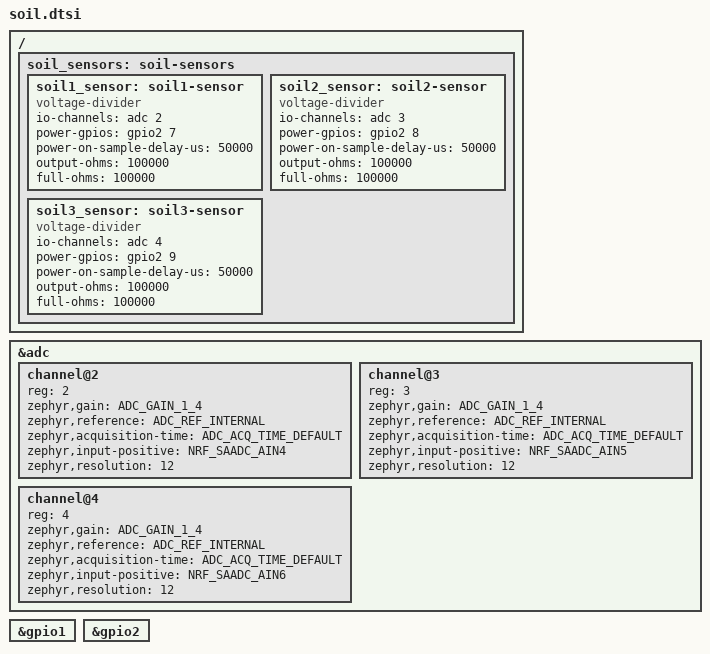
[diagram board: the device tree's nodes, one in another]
&adc {
	status = "okay";
	#address-cells = <1>;
	#size-cells = <0>;

	channel@2 {
		reg = <2>;
		zephyr,gain = "ADC_GAIN_1_4";
		zephyr,reference = "ADC_REF_INTERNAL";
		zephyr,acquisition-time = <ADC_ACQ_TIME_DEFAULT>;
		zephyr,input-positive = <NRF_SAADC_AIN4>; /* P1.11 */
		zephyr,resolution = <12>;
	};

	channel@3 {
		reg = <3>;
		zephyr,gain = "ADC_GAIN_1_4";
		zephyr,reference = "ADC_REF_INTERNAL";
		zephyr,acquisition-time = <ADC_ACQ_TIME_DEFAULT>;
		zephyr,input-positive = <NRF_SAADC_AIN5>; /* P1.12 */
		zephyr,resolution = <12>;
	};

	channel@4 {
		reg = <4>;
		zephyr,gain = "ADC_GAIN_1_4";
		zephyr,reference = "ADC_REF_INTERNAL";
		zephyr,acquisition-time = <ADC_ACQ_TIME_DEFAULT>;
		zephyr,input-positive = <NRF_SAADC_AIN6>; /* P1.13 */
		zephyr,resolution = <12>;
	};
};

/ {
	soil_sensors: soil-sensors{
		soil1_sensor: soil1-sensor {
			compatible = "voltage-divider";
			status = "okay";
			io-channels = <&adc 2>;
			power-gpios = <&gpio2 7 GPIO_ACTIVE_HIGH>;
			power-on-sample-delay-us = <50000>; 
			output-ohms = <100000>;
			full-ohms = <100000>;
		};

		soil2_sensor: soil2-sensor {
			compatible = "voltage-divider";
			status = "okay";
			io-channels = <&adc 3>;
			power-gpios = <&gpio2 8 GPIO_ACTIVE_HIGH>;
			power-on-sample-delay-us = <50000>; 
			output-ohms = <100000>;
			full-ohms = <100000>;
		};

		soil3_sensor: soil3-sensor {
			compatible = "voltage-divider";
			status = "okay";
			io-channels = <&adc 4>;
			power-gpios = <&gpio2 9 GPIO_ACTIVE_HIGH>;
			power-on-sample-delay-us = <50000>; 
			output-ohms = <100000>;
			full-ohms = <100000>;
		};
	};
};

&gpio1 {
	status = "okay";
};

&gpio2 {
	status = "okay";
};
